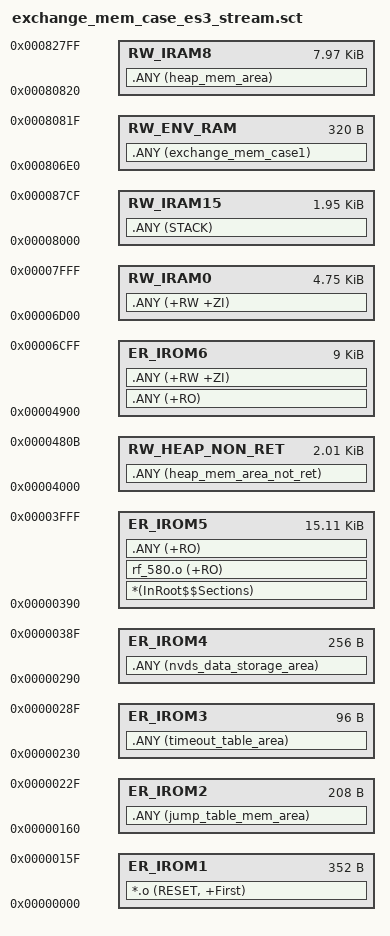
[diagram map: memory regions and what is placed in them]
; *************************************************************
; *** Scatter-Loading Description File generated by uVision ***
; *************************************************************

LR_IROM1 0x00000000 0x160 {  			; load region size_region
	ER_IROM1 0x00000000 0x160  {  		; load address = execution address
		*.o (RESET, +First)
	}
}
 
LR_IROM2  0x00000160 0x00d0 {			; 0x00000160 - 0x00000230
	ER_IROM2 0x00000160 0x00d0  {
		.ANY (jump_table_mem_area) 
	}
}

LR_IROM3 0x00000230 0x060 {				; 0x00000230 - 0x00000290
	ER_IROM3 0x00000230 0x060  {
		.ANY (timeout_table_area)
	}
}

LR_IROM4 0x00000290 0x0100 {			; 0x00000290 - 0x00000390
	ER_IROM4 0x00000290 0x0100  {
		.ANY (nvds_data_storage_area)
	}
}

LR_IROM5 0x00000390 0x3c70 {			; 0x00000390 - 0x00004000
	ER_IROM5 0x00000390 0x3c70  {
		*(InRoot$$Sections)				; All library sections that must be in a
										; root region, for example, __main.o,
										; __scatter*.o, __dc*.o, and * Region$$Table
		rf_580.o (+RO)
		.ANY (+RO) 
	}
}  

LR_IROM6  0x00004900 0x2400 {			; 0x00004900 - 0x00006d00
	ER_IROM6 0x00004900 0x2400  {
		.ANY (+RO) 
		.ANY (+RW +ZI)
	}
}

LR_HEAP_NON_RET 0x00004000 0x8fc {		; 0x00004000 - 0x000048fc	(size is 0x80C)
	RW_HEAP_NON_RET 0x00004000 0x80c  {
		.ANY (heap_mem_area_not_ret)    
	}
}

; ******* RAM *******
LR_IRAM0  0x00006d00 0x1300 {			; 0x00006d00 - 0x00008000
	RW_IRAM0 0x00006d00 0x1300 { 		; RW data
		.ANY (+RW +ZI)
	}
}

LR_IRAM1  0x00008000 0x1800 {			; 0x00008000 - 0x00009800
	RW_IRAM15 0x00008000 0x7d0 { 		; RW data
		.ANY (STACK)
	}

;	RW_IRAM5 0x000087d0 0x1030   {  	; RW data
;		.ANY (+RW +ZI)
;		hardfault_handler.o (+RW +ZI)
;	}
}

; ******* Retention RAM *******
LR_RET_RAM  0x000806e0 0x2920 {			; 0x000806e0 - 0x00083000
	RW_ENV_RAM 0x0000806e0 0x140 {		; 0x806dc is the last address used by the ROM code 
		.ANY (exchange_mem_case1) 
	}

    RW_IRAM8 0x000080820 0x00001FE0  {
        .ANY (heap_mem_area)
	}  
}

